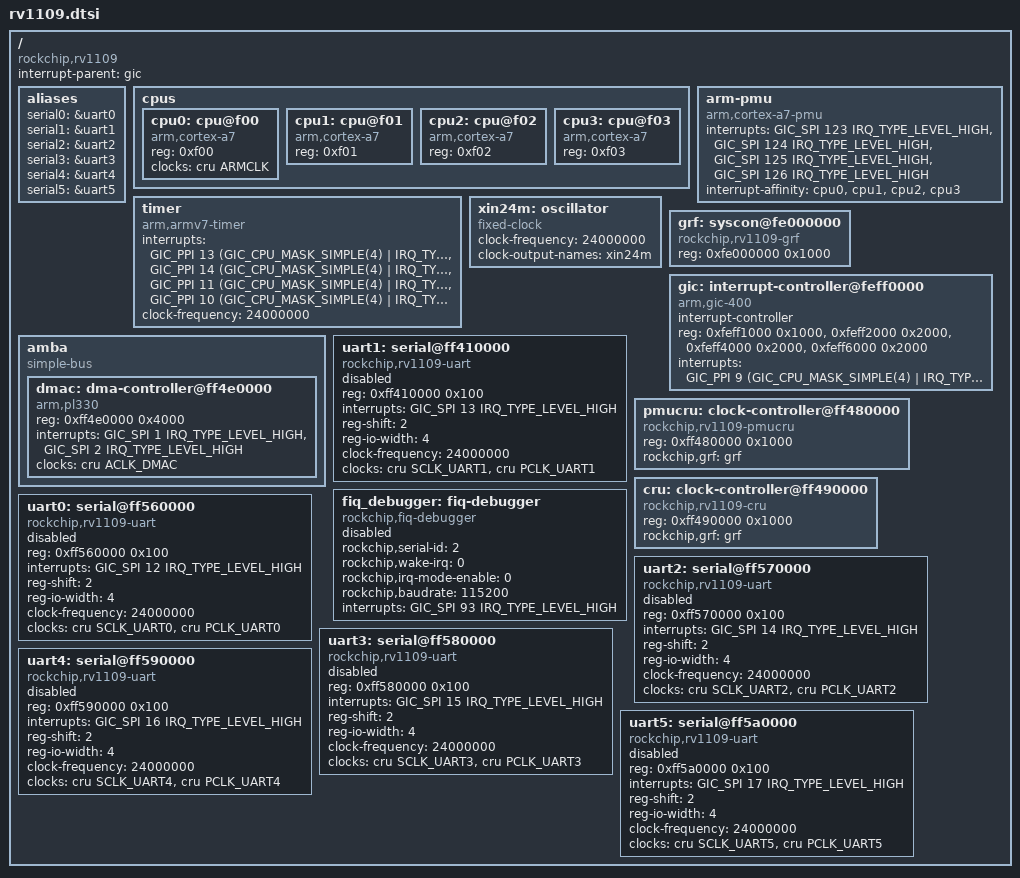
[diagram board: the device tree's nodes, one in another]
// SPDX-License-Identifier: (GPL-2.0+ OR MIT)
/*
 * Copyright (c) 2019 Fuzhou Rockchip Electronics Co., Ltd.
 */

#include <dt-bindings/clock/rv1109-cru.h>
#include <dt-bindings/gpio/gpio.h>
#include <dt-bindings/interrupt-controller/irq.h>
#include <dt-bindings/interrupt-controller/arm-gic.h>

/ {
	#address-cells = <1>;
	#size-cells = <1>;

	compatible = "rockchip,rv1109";

	interrupt-parent = <&gic>;

	aliases {
		serial0 = &uart0;
		serial1 = &uart1;
		serial2 = &uart2;
		serial3 = &uart3;
		serial4 = &uart4;
		serial5 = &uart5;
	};

	cpus {
		#address-cells = <1>;
		#size-cells = <0>;

		cpu0: cpu@f00 {
			device_type = "cpu";
			compatible = "arm,cortex-a7";
			reg = <0xf00>;
			clocks = <&cru ARMCLK>;
		};

		cpu1: cpu@f01 {
			device_type = "cpu";
			compatible = "arm,cortex-a7";
			reg = <0xf01>;
		};

		cpu2: cpu@f02 {
			device_type = "cpu";
			compatible = "arm,cortex-a7";
			reg = <0xf02>;
		};

		cpu3: cpu@f03 {
			device_type = "cpu";
			compatible = "arm,cortex-a7";
			reg = <0xf03>;
		};
	};

	arm-pmu {
		compatible = "arm,cortex-a7-pmu";
		interrupts = <GIC_SPI 123 IRQ_TYPE_LEVEL_HIGH>,
			     <GIC_SPI 124 IRQ_TYPE_LEVEL_HIGH>,
			     <GIC_SPI 125 IRQ_TYPE_LEVEL_HIGH>,
			     <GIC_SPI 126 IRQ_TYPE_LEVEL_HIGH>;
		interrupt-affinity = <&cpu0>, <&cpu1>, <&cpu2>, <&cpu3>;
	};

	timer {
		compatible = "arm,armv7-timer";
		interrupts = <GIC_PPI 13 (GIC_CPU_MASK_SIMPLE(4) | IRQ_TYPE_LEVEL_HIGH)>,
			     <GIC_PPI 14 (GIC_CPU_MASK_SIMPLE(4) | IRQ_TYPE_LEVEL_HIGH)>,
			     <GIC_PPI 11 (GIC_CPU_MASK_SIMPLE(4) | IRQ_TYPE_LEVEL_HIGH)>,
			     <GIC_PPI 10 (GIC_CPU_MASK_SIMPLE(4) | IRQ_TYPE_LEVEL_HIGH)>;
		clock-frequency = <24000000>;
	};

	xin24m: oscillator {
		compatible = "fixed-clock";
		clock-frequency = <24000000>;
		clock-output-names = "xin24m";
		#clock-cells = <0>;
	};

	grf: syscon@fe000000 {
		compatible = "rockchip,rv1109-grf", "syscon";
		reg = <0xfe000000 0x1000>;
	};

	gic: interrupt-controller@feff0000 {
		compatible = "arm,gic-400";
		interrupt-controller;
		#interrupt-cells = <3>;
		#address-cells = <0>;

		reg = <0xfeff1000 0x1000>,
		      <0xfeff2000 0x2000>,
		      <0xfeff4000 0x2000>,
		      <0xfeff6000 0x2000>;
		interrupts = <GIC_PPI 9 (GIC_CPU_MASK_SIMPLE(4) | IRQ_TYPE_LEVEL_HIGH)>;
	};

	amba {
		compatible = "simple-bus";
		#address-cells = <1>;
		#size-cells = <1>;
		ranges;

		dmac: dma-controller@ff4e0000 {
			compatible = "arm,pl330", "arm,primecell";
			reg = <0xff4e0000 0x4000>;
			interrupts = <GIC_SPI 1 IRQ_TYPE_LEVEL_HIGH>,
				     <GIC_SPI 2 IRQ_TYPE_LEVEL_HIGH>;
			#dma-cells = <1>;
			clocks = <&cru ACLK_DMAC>;
			clock-names = "apb_pclk";
		};
	};

	uart1: serial@ff410000 {
		compatible = "rockchip,rv1109-uart", "snps,dw-apb-uart";
		reg = <0xff410000 0x100>;
		interrupts = <GIC_SPI 13 IRQ_TYPE_LEVEL_HIGH>;
		reg-shift = <2>;
		reg-io-width = <4>;
		clock-frequency = <24000000>;
		clocks = <&cru SCLK_UART1>, <&cru PCLK_UART1>;
		clock-names = "baudclk", "apb_pclk";
		status = "disabled";
	};

	pmucru: clock-controller@ff480000 {
		compatible = "rockchip,rv1109-pmucru";
		reg = <0xff480000 0x1000>;
		rockchip,grf = <&grf>;
		#clock-cells = <1>;
		#reset-cells = <1>;
	};

	cru: clock-controller@ff490000 {
		compatible = "rockchip,rv1109-cru";
		reg = <0xff490000 0x1000>;
		rockchip,grf = <&grf>;
		#clock-cells = <1>;
		#reset-cells = <1>;
	};

	fiq_debugger: fiq-debugger {
		compatible = "rockchip,fiq-debugger";
		rockchip,serial-id = <2>;
		rockchip,wake-irq = <0>;
		rockchip,irq-mode-enable = <0>;
		rockchip,baudrate = <115200>;  /* Only 115200 and 1500000 */
		interrupts = <GIC_SPI 93 IRQ_TYPE_LEVEL_HIGH>;
		status = "disabled";
	};

	uart0: serial@ff560000 {
		compatible = "rockchip,rv1109-uart", "snps,dw-apb-uart";
		reg = <0xff560000 0x100>;
		interrupts = <GIC_SPI 12 IRQ_TYPE_LEVEL_HIGH>;
		reg-shift = <2>;
		reg-io-width = <4>;
		clock-frequency = <24000000>;
		clocks = <&cru SCLK_UART0>, <&cru PCLK_UART0>;
		clock-names = "baudclk", "apb_pclk";
		status = "disabled";
	};

	uart2: serial@ff570000 {
		compatible = "rockchip,rv1109-uart", "snps,dw-apb-uart";
		reg = <0xff570000 0x100>;
		interrupts = <GIC_SPI 14 IRQ_TYPE_LEVEL_HIGH>;
		reg-shift = <2>;
		reg-io-width = <4>;
		clock-frequency = <24000000>;
		clocks = <&cru SCLK_UART2>, <&cru PCLK_UART2>;
		clock-names = "baudclk", "apb_pclk";
		status = "disabled";
	};

	uart3: serial@ff580000 {
		compatible = "rockchip,rv1109-uart", "snps,dw-apb-uart";
		reg = <0xff580000 0x100>;
		interrupts = <GIC_SPI 15 IRQ_TYPE_LEVEL_HIGH>;
		reg-shift = <2>;
		reg-io-width = <4>;
		clock-frequency = <24000000>;
		clocks = <&cru SCLK_UART3>, <&cru PCLK_UART3>;
		clock-names = "baudclk", "apb_pclk";
		status = "disabled";
	};

	uart4: serial@ff590000 {
		compatible = "rockchip,rv1109-uart", "snps,dw-apb-uart";
		reg = <0xff590000 0x100>;
		interrupts = <GIC_SPI 16 IRQ_TYPE_LEVEL_HIGH>;
		reg-shift = <2>;
		reg-io-width = <4>;
		clock-frequency = <24000000>;
		clocks = <&cru SCLK_UART4>, <&cru PCLK_UART4>;
		clock-names = "baudclk", "apb_pclk";
		status = "disabled";
	};

	uart5: serial@ff5a0000 {
		compatible = "rockchip,rv1109-uart", "snps,dw-apb-uart";
		reg = <0xff5a0000 0x100>;
		interrupts = <GIC_SPI 17 IRQ_TYPE_LEVEL_HIGH>;
		reg-shift = <2>;
		reg-io-width = <4>;
		clock-frequency = <24000000>;
		clocks = <&cru SCLK_UART5>, <&cru PCLK_UART5>;
		clock-names = "baudclk", "apb_pclk";
		status = "disabled";
	};
};
